# STM32H7x7_CM7 register map
File version: 1.0
CPU: CM7 r0p1, little endian, MPU, FPU, 4 interrupt priority bits
Registers are 32-bit, read-write, reset 0x0 unless marked. A register's access mark holds for its fields unless they carry their own. Offsets are from the block's base; [hi:lo] are bit positions; {n}, {i} and the like mark numbered series.

## DCMI — Digital camera interface
Base 0x48020000
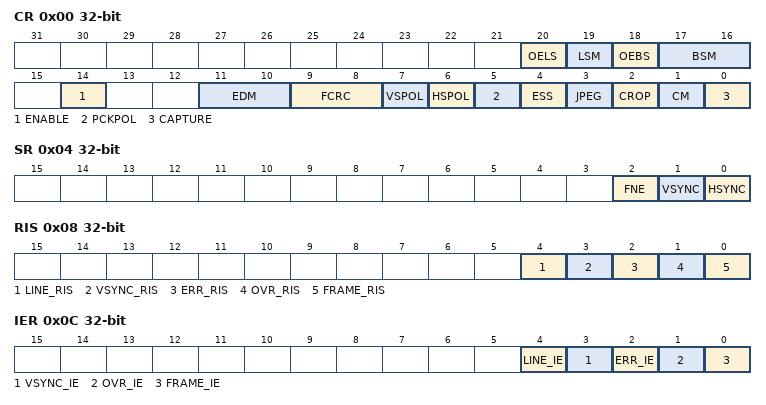
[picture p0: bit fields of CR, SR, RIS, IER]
0x00 CR — control register 1
  [20] OELS — Odd/Even Line Select (Line Select Start)
  [19] LSM — Line Select mode
  [18] OEBS — Odd/Even Byte Select (Byte Select Start)
  [17:16] BSM — Byte Select mode
  [14] ENABLE — DCMI enable
  [11:10] EDM — Extended data mode
  [9:8] FCRC — Frame capture rate control
  [7] VSPOL — Vertical synchronization polarity
  [6] HSPOL — Horizontal synchronization polarity
  [5] PCKPOL — Pixel clock polarity
  [4] ESS — Embedded synchronization select
  [3] JPEG — JPEG format
  [2] CROP — Crop feature
  [1] CM — Capture mode
  [0] CAPTURE — Capture enable
0x04 SR ro — status register
  [2] FNE — FIFO not empty
  [1] VSYNC
  [0] HSYNC
0x08 RIS ro — raw interrupt status register
  [4] LINE_RIS — Line raw interrupt status
  [3] VSYNC_RIS — VSYNC raw interrupt status
  [2] ERR_RIS — Synchronization error raw interrupt status
  [1] OVR_RIS — Overrun raw interrupt status
  [0] FRAME_RIS — Capture complete raw interrupt status
0x0C IER — interrupt enable register
  [4] LINE_IE — Line interrupt enable
  [3] VSYNC_IE — VSYNC interrupt enable
  [2] ERR_IE — Synchronization error interrupt enable
  [1] OVR_IE — Overrun interrupt enable
  [0] FRAME_IE — Capture complete interrupt enable
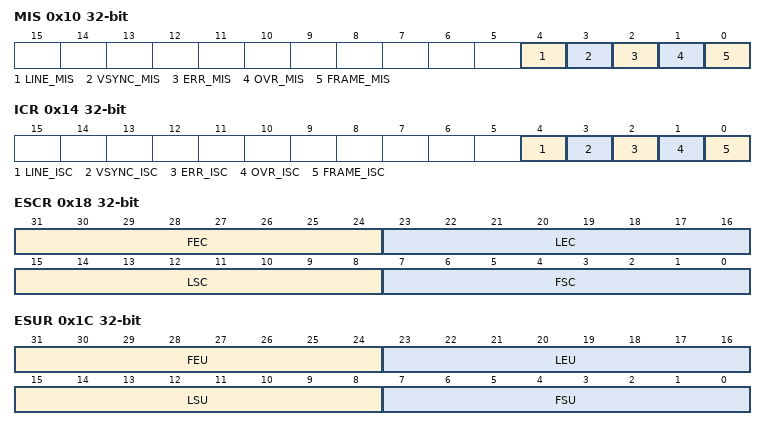
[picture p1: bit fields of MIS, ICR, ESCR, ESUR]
0x10 MIS ro — masked interrupt status register
  [4] LINE_MIS — Line masked interrupt status
  [3] VSYNC_MIS — VSYNC masked interrupt status
  [2] ERR_MIS — Synchronization error masked interrupt status
  [1] OVR_MIS — Overrun masked interrupt status
  [0] FRAME_MIS — Capture complete masked interrupt status
0x14 ICR wo — interrupt clear register
  [4] LINE_ISC — line interrupt status clear
  [3] VSYNC_ISC — Vertical synch interrupt status clear
  [2] ERR_ISC — Synchronization error interrupt status clear
  [1] OVR_ISC — Overrun interrupt status clear
  [0] FRAME_ISC — Capture complete interrupt status clear
0x18 ESCR — embedded synchronization code register
  [31:24] FEC — Frame end delimiter code
  [23:16] LEC — Line end delimiter code
  [15:8] LSC — Line start delimiter code
  [7:0] FSC — Frame start delimiter code
0x1C ESUR — embedded synchronization unmask register
  [31:24] FEU — Frame end delimiter unmask
  [23:16] LEU — Line end delimiter unmask
  [15:8] LSU — Line start delimiter unmask
  [7:0] FSU — Frame start delimiter unmask
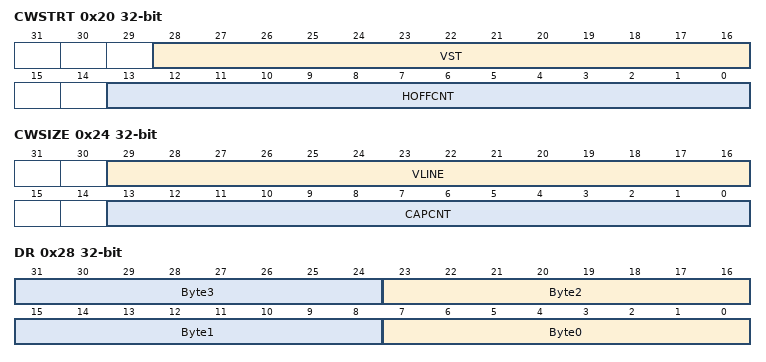
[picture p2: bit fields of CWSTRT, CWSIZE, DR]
0x20 CWSTRT — crop window start
  [28:16] VST — Vertical start line count
  [13:0] HOFFCNT — Horizontal offset count
0x24 CWSIZE — crop window size
  [29:16] VLINE — Vertical line count
  [13:0] CAPCNT — Capture count
0x28 DR ro — data register
  [8n+7:8n] Byte{n} (n=0..3) — Data byte {n}

## MDIOS — Management data input/output slave
Base 0x40009400
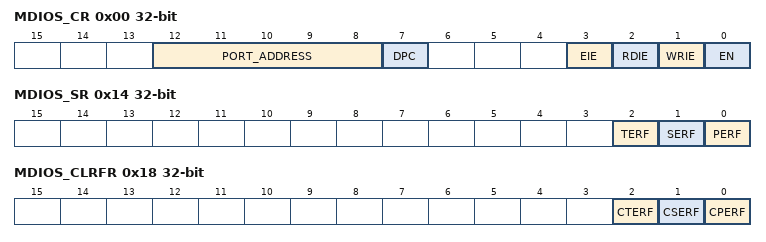
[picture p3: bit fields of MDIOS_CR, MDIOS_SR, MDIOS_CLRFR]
0x00 MDIOS_CR — MDIOS configuration register
  [12:8] PORT_ADDRESS — Slaves's address
  [7] DPC — Disable Preamble Check
  [3] EIE — Error interrupt enable
  [2] RDIE — Register Read Interrupt Enable
  [1] WRIE — Register write interrupt enable
  [0] EN — Peripheral enable
0x04 MDIOS_WRFR ro — MDIOS write flag register
  [31:0] WRF — Write flags for MDIO registers 0 to 31
0x08 MDIOS_CWRFR — MDIOS clear write flag register
  [31:0] CWRF — Clear the write flag
0x0C MDIOS_RDFR ro — MDIOS read flag register
  [31:0] RDF — Read flags for MDIO registers 0 to 31
0x10 MDIOS_CRDFR — MDIOS clear read flag register
  [31:0] CRDF — Clear the read flag
0x14 MDIOS_SR ro — MDIOS status register
  [2] TERF — Turnaround error flag
  [1] SERF — Start error flag
  [0] PERF — Preamble error flag
0x18 MDIOS_CLRFR — MDIOS clear flag register
  [2] CTERF — Clear the turnaround error flag
  [1] CSERF — Clear the start error flag
  [0] CPERF — Clear the preamble error flag
{0x1C+4i} MDIOS_DINR{i} ro (i=0..31) — MDIOS input data register {i}
  [15:0] DIN{i} — Input data received from MDIO Master during write frames
{0x9C+4i} MDIOS_DOUTR{i} (i=0..31) — MDIOS output data register {i}
  [15:0] DOUT{i} — Output data sent to MDIO Master during read frames
